# ISP6P5_SYS1 register map
Vendor: Texas Instruments
Peripheral module from a debugger description file (folder TDA2Px).
Registers are 32-bit, access per field, reset 0x0 unless marked. A register's access mark holds for its fields unless they carry their own. Offsets are as the file gives them; lines under a group give offsets from that group; [hi:lo] are bit positions; {n}, {i} and the like mark numbered series; 'fields as' and 'values as' point back to an identical list; <NAME> marks a mode.

## ISP6P5_SYS1
0x00 ISP5_REVISION ro reset not defined — IP Revision Identifier (X.Y.R) Used by software to track features, bugs, and compatibility
  [31:0] REVISION — IP Revision
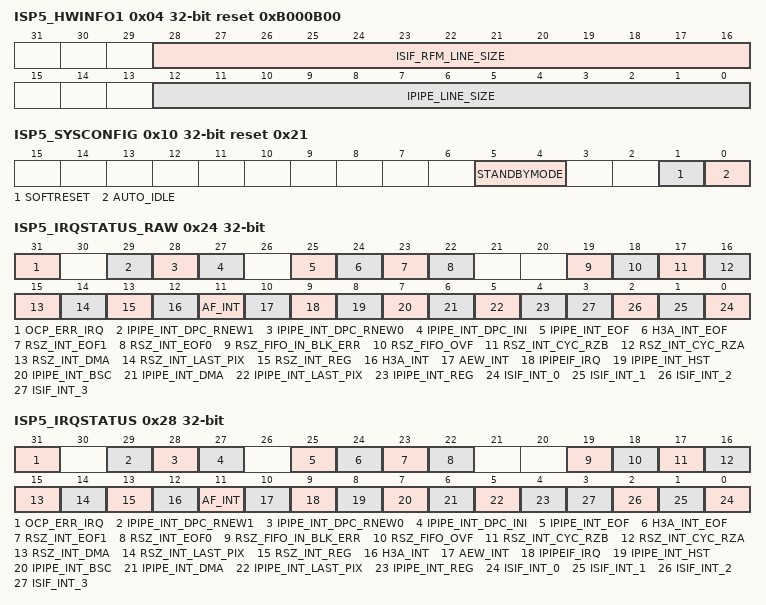
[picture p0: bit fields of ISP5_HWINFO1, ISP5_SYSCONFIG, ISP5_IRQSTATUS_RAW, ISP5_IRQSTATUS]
0x04 ISP5_HWINFO1 ro reset 0xB000B00 — GENERIC PARAMETER REGISTER Information about the IP module's hardware configuration. Actual field format and encoding is up to the module's designer to decide.
  [28:16] ISIF_RFM_LINE_SIZE — Memory line size for the data reformatter in the ISIF module.
  [12:0] IPIPE_LINE_SIZE — Memory line size for the IPIPE module
0x08 ISP5_HWINFO2 ro reset 0xB00 — GENERIC PARAMETER REGISTER Information about the IP module's hardware configuration. Actual field format and encoding is up to the module's designer to decide.
  [12:0] H3A_LINE_SIZE — Memory line size for the H3A module
0x10 ISP5_SYSCONFIG reset 0x21 — Clock management configuration
  [5:4] STANDBYMODE rw — Configuration of the local initiator state management mode. By definition, initiator may generate read/write transaction as long as it is out of STANDBY state.
    0=FORCE (Force-standby mode: local initiator is unconditionally placed in standby state. Backup mode, for debug only.); 1=NO (No-standby mode: local initiator is unconditionally placed out of standby state. Backup mode, for debug only.); 2=SMART (Smart-standby mode: local initiator standby status depends on local conditions, i.e. the module's functional requirement from the initiator. IP module shall not generate (initiator-related) wakeup events. Generation of the MStandby signal shall be initiated by the firmware by writing.MSTANDBY = ?1?.)
  [1] SOFTRESET rw — Software reset. The soft reset will cause the MStandby to be asserted as the reset value of theISP5_CTRL.MSTANDBY bit is 1. After a soft reset, the software shall ensure not to perform any access for 16 clock cycles (OCP-slave port frequency) after writing this bit. The OCP slave port is running at half the frequency of the functional clock. Before issuing a soft reset, the software shall ensure that no more traffic is being generated by the ISP5. Basically, it means that either the camera module shall be stopped from sending data and/or that the ISP5 modules are disabled. The last interrupt triggered by the ISP5 design upon completion of the frame processing is rsz_int_dma. This rsz_int_dma event shall be used to enable clean termination of the processing. The software shall wait a few hundred cycles to trigger the soft reset after upon assertion of the rsz_int_dma, this is to ensure that the BL is completely drained. Furthermore the software shall set the ISP5 in standbymode before issuing the soft reset: Set ISP5_SYSCONFIG.STANDBYMODE = 2 (smart standby) Set ISP5_CTRL.MSTANDBY to ?1? Poll for ISP5_CTRL.MSTANDBY_WAIT = 1. Then, the soft reset can be applied ISP5_SYSCONFIG.SOFTRESET = 1.
    0=DONE (Reset done, no pending action); 1=PENDING (Reset (software or other) ongoing)
  [0] AUTO_IDLE ro — Auto clock gating. Always enabled.
0x20 ISP5_IRQ_EOI — End Of Interrupt number specification
  [1:0] LINE_NUMBER rw — Software End Of Interrupt (EOI) control. Write number of interrupt output.
    0=READ0 (Reads always 0 (no EOI memory)); 1=EOI1 (EOI for interrupt output line #1); 3=EOI3 (EOI for interrupt output line #3); 2=EOI2 (EOI for interrupt output line #2)
0x24 ISP5_IRQSTATUS_RAW — Per-event raw interrupt status vector. Raw status is set even if event is not enabled. Write 1 to set the (raw) status, mostly for debug. The ISP5 outputs 4 interrupt lines ISP5_IRQ0 to ISP5_IRQ3. Any internal ISP5 event can be merged on the 4 lines. A same event shall be enabled on only one interrupt line. There is another interrupt register in the memory map, look for2
  [all] fields
    0=NOACTION; 1=SET (Set event (debug))
  [31] OCP_ERR_IRQ rw — An OCP error has been received on the ISP5 master port.
  [29] IPIPE_INT_DPC_RNEW1 rw
  [28] IPIPE_INT_DPC_RNEW0 rw
  [27] IPIPE_INT_DPC_INI rw
  [25] IPIPE_INT_EOF rw
  [24] H3A_INT_EOF rw
  [23] RSZ_INT_EOF1 rw — RESIZER module event: This event signals that the BL has received the eof signal from the resizer B engine which happens one the last transfer in the frame has happened. Note that because the BL has FIFOs it may take some additional time before true data transfter completion to memory.
  [22] RSZ_INT_EOF0 rw — RESIZER module event: This event signals that the BL has received the eof signal from the resizer A engine which happens one the last transfer in the frame has happened. Note that because the BL has FIFOs it may take some additional time before true data transfter completion to memory.
  [19] RSZ_FIFO_IN_BLK_ERR rw — This event signals that the minimum vertical blanking period has not been respected causing errors in the input data buffering submodule. This event will be triggered when the rsz_int_reg event of frame N is triggered before the rsz_int_dma of frame N + 1. This event would typically happen at the transition between two frames because there is not enough vertical blanking between frames: the firmware shall take care to ensure enough vertical blanking. The hardware cannot recover from this error. It will be required to perform a reset of the IP.
  [18] RSZ_FIFO_OVF rw — Resizer module overflow This event is set when overflow happens in the RESIZER module. This event would typically happen while processing a frame because the video port pixel clock is too high: the firmware shall take care to use a lower pixel clock at the input of the resizer module. Depending on the mode bein used, the overflow can happen at different places: 1. Bypass mode: overflow happened in the input circular buffer. 2. Pass through mode: overflow happened on the module output interface (MTC) 3. Normal resize mode: overflow happened in the input circular buffer. This event signals that overflow happened in the input data buffering submodule. 1. In normal resizer mode or bypass mode, this event will be triggered when the This event would typically happen while processing a frame because the video port pixel clock is too high: the firmware shall take care to use a lower pixel clock at the input of the resizer module. The hardware cannot recover from this error. It will be required to perform a reset of the IP.
  [17] RSZ_INT_CYC_RZB rw — RESIZER module event: This event is the circular interrupt for RESIZER #B. An event can be triggered every time thatRSZ_IRQ_RZB output lines have been written out to the RZB_SDR_Y buffer. The range can go from 1 to 8192 lines. Usually, this value should be such that the circular buffer vertical size (set by the RZB_SDR_Y_PTR_E register) is a multiple of RSZ_IRQ_RZB. Note that at the time the interrupt is triggered, the actual data write has not taken place. It may take a few hundred of cycles to complete the data write into system memory. This is not an issue since the start of the buffer is read first.
  [16] RSZ_INT_CYC_RZA rw — RESIZER module event: This event is the circular interrupt for RESIZER #A. An event can be triggered every time thatRSZ_IRQ_RZA output lines have been written out to the RZA_SDR_Y buffer. The range can go from 1 to 8192 lines. Usually, the circular buffer vertical size (set by the RZA_SDR_Y_PTR_E register) should be a multiple of RSZ_IRQ_RZA. Note that at the time the interrupt is triggered, the actual data write has not taken place. It may take a few hundred of cycles to complete the data write into system memory. This is not an issue since the start of the buffer is read first.
  [15] RSZ_INT_DMA rw — This event is triggered when the last eof (of the two MTC interfaces) is sent out to the BL and that the resizer core has returned to idle. rsz_int_dma is a true indication that all processing is finished for the particular frame on both resizer engines.
  [14] RSZ_INT_LAST_PIX rw — This event is triggered when the last pixel of the valid area is received.
  [13] RSZ_INT_REG rw — This event is triggered when the first pixel of the valid area is received. Shadowed registers can be updated at any time but the new value will take effect on the next rsz_int_reg event.
  [12] H3A_INT rw
  [11] AF_INT rw
  [10] AEW_INT rw
  [9] IPIPEIF_IRQ rw — IPIPEIF module interrupt
  [8] IPIPE_INT_HST rw
  [7] IPIPE_INT_BSC rw
  [6] IPIPE_INT_DMA rw
  [5] IPIPE_INT_LAST_PIX rw
  [4] IPIPE_INT_REG rw
  [n] ISIF_INT_{n} rw (n=0..3)
0x28 ISP5_IRQSTATUS — Per-event 'enabled' interrupt status vector. Enabled status isn't set unless event is enabled. Write 1 to clear the status after interrupt has been serviced (raw status gets cleared, i.e. even if not enabled). The ISP5 outputs 4 interrupt lines ISP5_IRQ0 to ISP5_IRQ3. Any internal ISP5 event can be merged on the 4 lines. A same event shall be enabled on only one interrupt line. There is another interrupt register in the memory map, look for2
  [all] fields
    0=NOACTION; 1=CLEAR (Clear (raw) event)
  [31] OCP_ERR_IRQ rw — An OCP error has been received on the ISP5 master port.
  [29] IPIPE_INT_DPC_RNEW1 rw
  [28] IPIPE_INT_DPC_RNEW0 rw
  [27] IPIPE_INT_DPC_INI rw
  [25] IPIPE_INT_EOF rw
  [24] H3A_INT_EOF rw
  [23] RSZ_INT_EOF1 rw — RESIZER module event: This event signals that the BL has received the eof signal from the resizer B engine which happens one the last transfer in the frame has happened. Note that because the BL has FIFOs it may take some additional time before true data transfter completion to memory.
  [22] RSZ_INT_EOF0 rw — RESIZER module event: This event signals that the BL has received the eof signal from the resizer A engine which happens one the last transfer in the frame has happened. Note that because the BL has FIFOs it may take some additional time before true data transfter completion to memory.
  [19] RSZ_FIFO_IN_BLK_ERR rw — This event signals that the minimum vertical blanking period has not been respected causing errors in the input data buffering submodule. This event will be triggered when the rsz_int_reg event of frame N is triggered before the rsz_int_dma of frame N + 1. This event would typically happen at the transition between two frames because there is not enough vertical blanking between frames: the firmware shall take care to ensure enough vertical blanking. The hardware cannot recover from this error. It will be required to perform a reset of the IP.
  [18] RSZ_FIFO_OVF rw — This event would typically happen while processing a frame because the video port pixel clock is too high: the firmware shall take care to use a lower pixel clock at the input of the resizer module. The hardware cannot recover from this error. It will be required to perform a reset of the IP.
  [17] RSZ_INT_CYC_RZB rw — RESIZER module event: This event is the circular interrupt for RESIZER #B. An event can be triggered every time thatRSZ_IRQ_RZB output lines have been written out to the RZB_SDR_Y buffer. The range can go from 1 to 8192 lines. Usually, this value should be such that the circular buffer vertical size (set by the RZB_SDR_Y_PTR_E register) is a multiple of RSZ_IRQ_RZB. Note that at the time the interrupt is triggered, the actual data write has not taken place. It may take a few hundred of cycles to complete the data write into system memory. This is not an issue since the start of the buffer is read first.
  [16] RSZ_INT_CYC_RZA rw — RESIZER module event: This event is the circular interrupt for RESIZER #A. An event can be triggered every time thatRSZ_IRQ_RZA output lines have been written out to the RZA_SDR_Y buffer. The range can go from 1 to 8192 lines. Usually, the circular buffer vertical size (set by the RZA_SDR_Y_PTR_E register) should be a multiple of RSZ_IRQ_RZA. Note that at the time the interrupt is triggered, the actual data write has not taken place. It may take a few hundred of cycles to complete the data write into system memory. This is not an issue since the start of the buffer is read first.
  [15] RSZ_INT_DMA rw — This event is triggered when the last eof (of the two MTC interfaces) is sent out to the BL and that the resizer core has returned to idle. rsz_int_dma is a true indication that all processing is finished for the particular frame on both resizer engines.
  [14] RSZ_INT_LAST_PIX rw — This event is triggered when the last pixel of the valid area is received.
  [13] RSZ_INT_REG rw — This event is triggered when the first pixel of the valid area is received. Shadowed registers can be updated at any time but the new value will take effect on the next rsz_int_reg event.
  [12] H3A_INT rw
  [11] AF_INT rw
  [10] AEW_INT rw
  [9] IPIPEIF_IRQ rw — IPIPEIF module interrupt
  [8] IPIPE_INT_HST rw
  [7] IPIPE_INT_BSC rw
  [6] IPIPE_INT_DMA rw
  [5] IPIPE_INT_LAST_PIX rw
  [4] IPIPE_INT_REG rw
  [n] ISIF_INT_{n} rw (n=0..3)
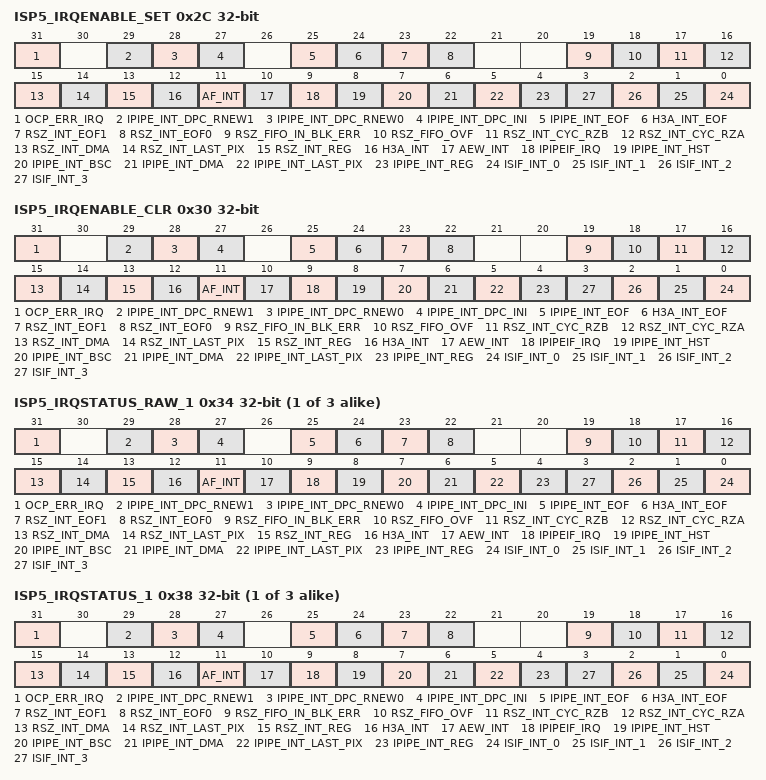
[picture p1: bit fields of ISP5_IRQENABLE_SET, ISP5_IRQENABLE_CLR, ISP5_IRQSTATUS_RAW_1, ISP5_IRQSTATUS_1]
0x2C ISP5_IRQENABLE_SET — Per-event interrupt enable bit vector. Write 1 to set (enable interrupt). Readout equal to corresponding _CLR register. The ISP5 outputs 4 interrupt lines ISP5_IRQ0 to ISP5_IRQ3. Any internal ISP5 event can be merged on the 4 lines. A same event shall be enabled on only one interrupt line. There is another interrupt register in the memory map, look for2.
  [all] fields
    0=NOACTION; 1=ENABLE (Enable interrupt)
  [31] OCP_ERR_IRQ rw — An OCP error has been received on the ISP5 master port.
  [29] IPIPE_INT_DPC_RNEW1 rw
  [28] IPIPE_INT_DPC_RNEW0 rw
  [27] IPIPE_INT_DPC_INI rw
  [25] IPIPE_INT_EOF rw
  [24] H3A_INT_EOF rw
  [23] RSZ_INT_EOF1 rw — RESIZER module event: This event signals that the BL has received the eof signal from the resizer B engine which happens one the last transfer in the frame has happened. Note that because the BL has FIFOs it may take some additional time before true data transfter completion to memory.
  [22] RSZ_INT_EOF0 rw — RESIZER module event: This event signals that the BL has received the eof signal from the resizer A engine which happens one the last transfer in the frame has happened. Note that because the BL has FIFOs it may take some additional time before true data transfter completion to memory.
  [19] RSZ_FIFO_IN_BLK_ERR rw — This event signals that the minimum vertical blanking period has not been respected causing errors in the input data buffering submodule. This event will be triggered when the rsz_int_reg event of frame N is triggered before the rsz_int_dma of frame N + 1. This event would typically happen at the transition between two frames because there is not enough vertical blanking between frames: the firmware shall take care to ensure enough vertical blanking. The hardware cannot recover from this error. It will be required to perform a reset of the IP.
  [18] RSZ_FIFO_OVF rw — This event would typically happen while processing a frame because the video port pixel clock is too high: the firmware shall take care to use a lower pixel clock at the input of the resizer module. The hardware cannot recover from this error. It will be required to perform a reset of the IP.
  [17] RSZ_INT_CYC_RZB rw — RESIZER module event: This event is the circular interrupt for RESIZER #B. An event can be triggered every time thatRSZ_IRQ_RZB output lines have been written out to the RZB_SDR_Y buffer. The range can go from 1 to 8192 lines. Usually, this value should be such that the circular buffer vertical size (set by the RZB_SDR_Y_PTR_E register) is a multiple of RSZ_IRQ_RZB. Note that at the time the interrupt is triggered, the actual data write has not taken place. It may take a few hundred of cycles to complete the data write into system memory. This is not an issue since the start of the buffer is read first.
  [16] RSZ_INT_CYC_RZA rw — RESIZER module event: This event is the circular interrupt for RESIZER #A. An event can be triggered every time thatRSZ_IRQ_RZA output lines have been written out to the RZA_SDR_Y buffer. The range can go from 1 to 8192 lines. Usually, the circular buffer vertical size (set by the RZA_SDR_Y_PTR_E register) should be a multiple of RSZ_IRQ_RZA. Note that at the time the interrupt is triggered, the actual data write has not taken place. It may take a few hundred of cycles to complete the data write into system memory. This is not an issue since the start of the buffer is read first.
  [15] RSZ_INT_DMA rw — This event is triggered when the last eof (of the two MTC interfaces) is sent out to the BL and that the resizer core has returned to idle. rsz_int_dma is a true indication that all processing is finished for the particular frame on both resizer engines.
  [14] RSZ_INT_LAST_PIX rw — This event is triggered when the last pixel of the valid area is received.
  [13] RSZ_INT_REG rw — This event is triggered when the first pixel of the valid area is received. Shadowed registers can be updated at any time but the new value will take effect on the next rsz_int_reg event.
  [12] H3A_INT rw
  [11] AF_INT rw
  [10] AEW_INT rw
  [9] IPIPEIF_IRQ rw — IPIPEIF module interrupt
  [8] IPIPE_INT_HST rw
  [7] IPIPE_INT_BSC rw
  [6] IPIPE_INT_DMA rw
  [5] IPIPE_INT_LAST_PIX rw
  [4] IPIPE_INT_REG rw
  [n] ISIF_INT_{n} rw (n=0..3)
0x30 ISP5_IRQENABLE_CLR — Per-event interrupt enable bit vector. Write 1 to clear (disable interrupt). Readout equal to corresponding _SET register. The ISP5 outputs 4 interrupt lines ISP5_IRQ0 to ISP5_IRQ3. Any internal ISP5 event can be merged on the 4 lines. A same event shall be enabled on only one interrupt line. There is another interrupt register in the memory map, look for2.
  [all] fields
    0=NOACTION; 1=DISABLE (Disable interrupt)
  [31] OCP_ERR_IRQ rw — An OCP error has been received on the ISP5 master port.
  [29] IPIPE_INT_DPC_RNEW1 rw
  [28] IPIPE_INT_DPC_RNEW0 rw
  [27] IPIPE_INT_DPC_INI rw
  [25] IPIPE_INT_EOF rw
  [24] H3A_INT_EOF rw
  [23] RSZ_INT_EOF1 rw — RESIZER module event: This event signals that the BL has received the eof signal from the resizer B engine which happens one the last transfer in the frame has happened. Note that because the BL has FIFOs it may take some additional time before true data transfter completion to memory.
  [22] RSZ_INT_EOF0 rw — RESIZER module event: This event signals that the BL has received the eof signal from the resizer A engine which happens one the last transfer in the frame has happened. Note that because the BL has FIFOs it may take some additional time before true data transfter completion to memory.
  [19] RSZ_FIFO_IN_BLK_ERR rw — This event signals that the minimum vertical blanking period has not been respected causing errors in the input data buffering submodule. This event will be triggered when the rsz_int_reg event of frame N is triggered before the rsz_int_dma of frame N + 1. This event would typically happen at the transition between two frames because there is not enough vertical blanking between frames: the firmware shall take care to ensure enough vertical blanking. The hardware cannot recover from this error. It will be required to perform a reset of the IP.
  [18] RSZ_FIFO_OVF rw — This event would typically happen while processing a frame because the video port pixel clock is too high: the firmware shall take care to use a lower pixel clock at the input of the resizer module. The hardware cannot recover from this error. It will be required to perform a reset of the IP.
  [17] RSZ_INT_CYC_RZB rw — RESIZER module event: This event is the circular interrupt for RESIZER #B. An event can be triggered every time thatRSZ_IRQ_RZB output lines have been written out to the RZB_SDR_Y buffer. The range can go from 1 to 8192 lines. Usually, this value should be such that the circular buffer vertical size (set by the RZB_SDR_Y_PTR_E register) is a multiple of RSZ_IRQ_RZB. Note that at the time the interrupt is triggered, the actual data write has not taken place. It may take a few hundred of cycles to complete the data write into system memory. This is not an issue since the start of the buffer is read first.
  [16] RSZ_INT_CYC_RZA rw — RESIZER module event: This event is the circular interrupt for RESIZER #A. An event can be triggered every time thatRSZ_IRQ_RZA output lines have been written out to the RZA_SDR_Y buffer. The range can go from 1 to 8192 lines. Usually, the circular buffer vertical size (set by the RZA_SDR_Y_PTR_E register) should be a multiple of RSZ_IRQ_RZA. Note that at the time the interrupt is triggered, the actual data write has not taken place. It may take a few hundred of cycles to complete the data write into system memory. This is not an issue since the start of the buffer is read first.
  [15] RSZ_INT_DMA rw — RESIZER module event: This event is triggered when the last eof (of the two MTC interfaces) is sent out to the BL and that the resizer core has returned to idle. rsz_int_dma is a true indication that all processing is finished for the particular frame on both resizer engines.
  [14] RSZ_INT_LAST_PIX rw — RESIZER module event: This event is triggered when the last pixel of the valid area is received.
  [13] RSZ_INT_REG rw — RESIZER module event: This event is triggered when the first pixel of the valid area is received. Shadowed registers can be updated at any time but the new value will take effect on the next rsz_int_reg event.
  [12] H3A_INT rw
  [11] AF_INT rw
  [10] AEW_INT rw
  [9] IPIPEIF_IRQ rw — IPIPEIF module interrupt
  [8] IPIPE_INT_HST rw
  [7] IPIPE_INT_BSC rw
  [6] IPIPE_INT_DMA rw
  [5] IPIPE_INT_LAST_PIX rw
  [4] IPIPE_INT_REG rw
  [n] ISIF_INT_{n} rw (n=0..3)
{0x24+0x10*i} ISP5_IRQSTATUS_RAW_{i} (i=1..3) — Per-event raw interrupt status vector. Raw status is set even if event is not enabled. Write 1 to set the (raw) status, mostly for debug. The ISP5 outputs 4 interrupt lines ISP5_IRQ0 to ISP5_IRQ3. Any internal ISP5 event can be merged on the 4 lines. A same event shall be enabled on only one interrupt line. There is another interrupt register in the memory map, look for2
  fields as ISP5_IRQSTATUS_RAW
{0x28+0x10*i} ISP5_IRQSTATUS_{i} (i=1..3) — Per-event 'enabled' interrupt status vector. Enabled status isn't set unless event is enabled. Write 1 to clear the status after interrupt has been serviced (raw status gets cleared, i.e. even if not enabled). The ISP5 outputs 4 interrupt lines ISP5_IRQ0 to ISP5_IRQ3. Any internal ISP5 event can be merged on the 4 lines. A same event shall be enabled on only one interrupt line. There is another interrupt register in the memory map, look for2
  fields as ISP5_IRQSTATUS
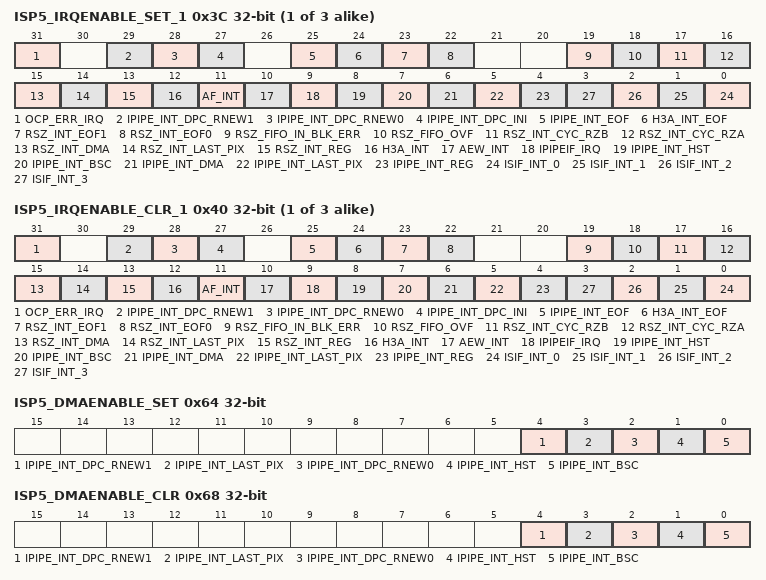
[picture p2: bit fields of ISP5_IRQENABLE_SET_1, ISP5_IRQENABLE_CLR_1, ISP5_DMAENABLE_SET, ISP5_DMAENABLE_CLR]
{0x2C+0x10*i} ISP5_IRQENABLE_SET_{i} (i=1..3) — Per-event interrupt enable bit vector. Write 1 to set (enable interrupt). Readout equal to corresponding _CLR register. The ISP5 outputs 4 interrupt lines ISP5_IRQ0 to ISP5_IRQ3. Any internal ISP5 event can be merged on the 4 lines. A same event shall be enabled on only one interrupt line. There is another interrupt register in the memory map, look for2.
  fields as ISP5_IRQENABLE_SET
{0x30+0x10*i} ISP5_IRQENABLE_CLR_{i} (i=1..3) — Per-event interrupt enable bit vector. Write 1 to clear (disable interrupt). Readout equal to corresponding _SET register. The ISP5 outputs 4 interrupt lines ISP5_IRQ0 to ISP5_IRQ3. Any internal ISP5 event can be merged on the 4 lines. A same event shall be enabled on only one interrupt line. There is another interrupt register in the memory map, look for2.
  fields as ISP5_IRQENABLE_CLR
0x64 ISP5_DMAENABLE_SET — Per-line DMA enable bit vector Write 1 to set (enable DMA request generation). Readout equal to corresponding _CLR register.
  [all] fields
    0=NOACTION; 1=ENABLE (Enable DMA)
  [4] IPIPE_INT_DPC_RNEW1 rw — Enable for ISP5 DMA request generation on line #2 This DMA request shall be set to transfer the DPC data from memory to the IPIPE internal RAM.
  [3] IPIPE_INT_LAST_PIX rw — Enable for ISP5 DMA request generation on line #3 This DMA request shall be set to transfer the GAMMA data from memory to the IPIPE internal RAM or to initialize the DPC table. One shall set theISP5_CTRL.DMA3_CFG register before enabling this DMA request.
  [2] IPIPE_INT_DPC_RNEW0 rw — Enable for ISP5 DMA request generation on line #2 This DMA request shall be set to transfer the DPC data from memory to the IPIPE internal RAM.
  [1] IPIPE_INT_HST rw — Enable for ISP5 DMA request generation on line #1 This DMA request shall be set to transfer the HIST data from the IPIPE internal RAM to memory.
  [0] IPIPE_INT_BSC rw — Enable for ISP5 DMA request generation on line #0 This DMA request shall be set to transfer the BSC data from the IPIPE internal RAM to memory.
0x68 ISP5_DMAENABLE_CLR — Per-line DMA clear bit vector Write 1 to clear (disable DMA request generation). Readout equal to corresponding _SET register.
  [all] fields
    0=NOACTION; 1=DISABLE (Disable DMA)
  [4] IPIPE_INT_DPC_RNEW1 rw — Clear for ISP5 DMA request generation on line ISP5_DMA_REQ[2]. This DMA request shall be set to transfer the DPC data from memory to the IPIPE internal RAM.
  [3] IPIPE_INT_LAST_PIX rw — Clear for ISP5 DMA request generation on ISP5_DMA_REQ[3]. This DMA request shall be set to transfer the GAMMA data from memory to the IPIPE internal RAM.
  [2] IPIPE_INT_DPC_RNEW0 rw — Clear for ISP5 DMA request generation on ISP5_DMA_REQ[2]. This DMA request shall be set to transfer the DPC data from memory to the IPIPE internal RAM.
  [1] IPIPE_INT_HST rw — Clear for ISP5 DMA request generation on ISP5_DMA_REQ[1]. This DMA request shall be set to transfer the HIST data from the IPIPE internal RAM to memory.
  [0] IPIPE_INT_BSC rw — Clear for ISP5 DMA request generation on ISP5_DMA_REQ[0]. This DMA request shall be set to transfer the BSC data from the IPIPE internal RAM to memory.
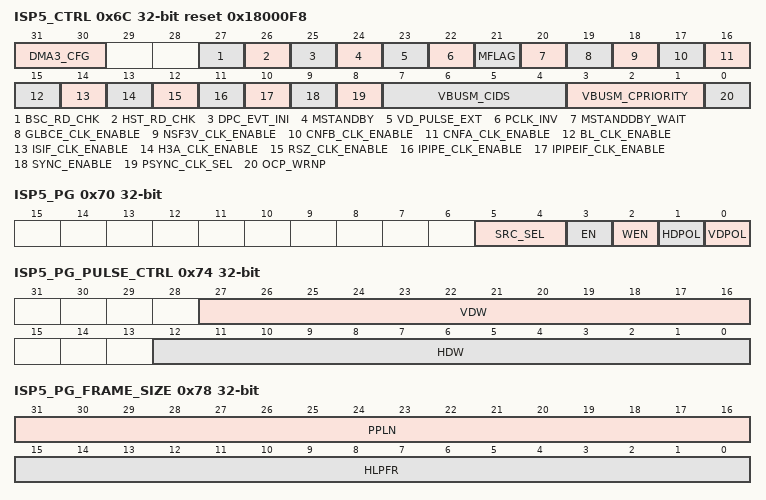
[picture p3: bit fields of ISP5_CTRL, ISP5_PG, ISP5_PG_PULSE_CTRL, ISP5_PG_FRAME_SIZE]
0x6C ISP5_CTRL reset 0x18000F8 — ISP5 CONTROL REGISTER
  [31:30] DMA3_CFG rw — This bitfield selects the DMA transfer configuration which is used with the ISP5_DMA_REQ[3] DMA request signal. This DMA request is generated from IPIPE_INT_LAST_PIXEL event. One can choose to use this DMA request to either transfer the DPC initialization data, the gamma table or both.
    0=NEWENUM1 (No DMA request associated with ISP5_DMA_REQ[3].); 1=NEWENUM2 (DPC DMA request associated with ISP5_DMA_REQ[3]. Expected DMA transfer size is 2 KBytes in the range 0x8000-0x87FF. DPC_EVT_INI shall be set to 0.); 3=NEWENUM4 (DPC + GAMMA DMA request associated with ISP5_DMA_REQ[3]. Expected DMA transfer size is 8 KBytes in the range 0x8000-0x87FF and 0xA800-0xBFFF. DPC_EVT_INI shall be set to 0.); 2=NEWENUM3 (GAMMA DMA request associated with ISP5_DMA_REQ[3]. Expected DMA transfer size is 6 KBytes in the range 0xA800-0xBFFF.)
  [27] BSC_RD_CHK rw — When the BSC computation is enabled and the BSC DMA request not used to read out the data, this register enables to ensure that the data were read fast enough, else an interrupt IPIPE_BSC_ERR is triggered. The hardware sets automatically this bit to 1 when software can start reading the memory. It is the software responsibility to set this bit to 0 after reading the data. Once the CPU has read the BSC data, it SHALL clear this register, else the PIPE_BSC_ERR will occur.
    0=NEWENUM1 (No interrupt generation can happen); 1=NEWENUM2 (The CPU can read the data from the memory. Needs to complete fast enough to avoid the interrupt generation.)
  [26] HST_RD_CHK rw — When the HISTOGRAM computation is enabled and the HST DMA request not used to read out the data, this register enables to ensure that the data were read fast enough, else an interrupt IPIPE_HST_ERR is triggered. The hardware sets automatically this bit to 1 when software can start reading the memory. It is the software responsibility to set this bit to 0 after reading the data. Once the CPU has read the histogram data, it SHALL clear this register, else the PIPE_HST_ERR will occur.
    values as BSC_RD_CHK
  [25] DPC_EVT_INI rw — Select the IPIPE module event to be used to generate the DMA requests for the DPC submodule.
    0=NEWENUM1 (IPIPE_INT_LAST_PIX event is selected.); 1=NEWENUM2 (IPIPE_INT_DPC_INI event is selected.)
  [24] MSTANDBY rw — MStandby signal assertion and de-assertion control for power management transitions. After software reset, this bit is asserted. Write '1' to transition from normal mode to idle mode. The firmware needs to ensure that no more ISP5 processing is ongoing before setting up this bit. Write '0' to transition from idle mode to normal mode. The software should pollISP5_CTRL.MSTANDBY_WAIT = ?0? after writing ISP5_CTRL.MSTANDBY = ?0? in a transition from idle to normal mode.
    0=NEWENUM1 (De-assert MStandby signal. May not be immediate due to power management handshaking btw the MStandby and Wait signals.); 1=NEWENUM2 (Assert MStandby signal)
  [23] VD_PULSE_EXT rw — VD pulse extension enable This bit enables or disables the VD extension bridge. By default, the bridge is enabled. At ISS level, it is expected that IPS5_CTRL.VD_PULSE_EXT = 1 when the VPORT gets data from the CSI2 RX module and IPS5_CTRL.VD_PULSE_EXT = 0 when the VPORT gets data from the parallel interface or the CCP2 RX module. There shall be at least three clock cycles between the time this bit is modified and the HD/VD pulse for start of frame comes.
    0=NEWENUM1 (Disabled); 1=NEWENUM2 (Enabled)
  [22] PCLK_INV rw — Pixel clock inversion This bit enables or disables pixel clock inversion. The ISP5 always samples the data on the rising edge of the pixel clock. Enabling the inversion shifts the resampling period by 1/2 a pixel clock period. PCLK needs to be disabled at ISS level before setting this bit.
    0=NEWENUM1 (Normal); 1=NEWENUM2 (Inversed)
  [21] MFLAG rw — MFlag signal generation control This bit controls how the OCP MFlag signal is generated on the ISS NOC.
    0=NEWENUM1 (The MFlag value is dynamic.); 1=NEWENUM2 (The MFlag value is static. The value is set with the.VBUSM_CPRIORITY bitfield.)
  [20] MSTANDDBY_WAIT ro — MStandby / Wait power management status bit. The power management framework of the ISP5 is based on the handshaking of the MStandby and Wait signals. The software is not supposed to write insidle the ISP5 slave port and initiate traffic whenISP5_CTRL.MSTANDBY bit is written. The software can poll this bit to know when MStandby signal is deasserted.
    0=NEWENUM1 (MStandby signal is de-asserted); 1=NEWENUM2 (MStandby signal is asserted)
  [19] GLBCE_CLK_ENABLE rw — GLBCE clock enable
    0=NEWENUM1 (Disable); 1=NEWENUM2 (Enable)
  [18] NSF3V_CLK_ENABLE rw — NSF3V clock enable
    0=NEWENUM1 (Disable); 1=NEWENUM2 (Enable)
  [17] CNFB_CLK_ENABLE rw — CNFB clock enable
    0=NEWENUM1 (Disable. Since CNF-B is removed , it doesn't have any effect); 1=NEWENUM2 (Enable. Since CNF-B is removed , it doesn't have any effect.)
  [16] CNFA_CLK_ENABLE rw — CNFA clock enable
    0=NEWENUM1 (Disable); 1=NEWENUM2 (Enable)
  [15] BL_CLK_ENABLE rw — BL clock enable
    0=NEWENUM1 (Disable); 1=NEWENUM2 (Enable)
  [14] ISIF_CLK_ENABLE rw — ISIF clock enable The ISP5 will return OCP_ERROR if one tries to program the module MMR or memory when the clock is disabled. There shall be at least three clock cycles between the time this bit is modified and the HD/VD pulse for start of frame comes.
    0=NEWENUM1 (Disable); 1=NEWENUM2 (Enable)
  [13] H3A_CLK_ENABLE rw — H3A clock enable The ISP5 will return OCP_ERROR if one tries to program the module MMR or memory when the clock is disabled.
    0=NEWENUM1 (Disable); 1=NEWENUM2 (Enable)
  [12] RSZ_CLK_ENABLE rw — RESIZER clock enable The ISP5 will return OCP_ERROR if one tries to program the module MMR or memory when the clock is disabled.
    0=NEWENUM1 (Disable); 1=NEWENUM2 (Enable)
  [11] IPIPE_CLK_ENABLE rw — IPIPE clock enable The ISP5 will return OCP_ERROR if one tries to program the module MMR or memory when the clock is disabled. If DPC is working before NSF3V (working as pre-NSF3V DPC), this bit must be asserted for SW to access DPC MMR entries.
    0=NEWENUM1 (Disable); 1=NEWENUM2 (Enable)
  [10] IPIPEIF_CLK_ENABLE rw — IPIPEIF clock enable The ISP5 will return OCP_ERROR if one tries to program the module MMR or memory when the clock is disabled.
    0=NEWENUM1 (Disable); 1=NEWENUM2 (Enable)
  [9] SYNC_ENABLE rw — PCLK Sync module enable
    0=NEWENUM1 (Disable. Shall only be used when the video port is not receiving data, e.g., data is read from the IPIPEIF module memory read port.); 1=NEWENUM2 (Enable. Shall be used when the video port is receiving data.)
  [8] PSYNC_CLK_SEL rw — PCLK Sync clock select. This bit selects the clock which is used to resynchronize the input pixel clock.
    0=NEWENUM1 (Use ISP6_CFG_CLK. Can be used if the input pixel clock is always lower than 213 MHz. Also, this option must not be chosen if DPC is used with CAL if (CAL - DPC - NSF3V - CAL case.)); 1=NEWENUM2 (ISP6_FUNC_CLK. Shall be used if the pixel clock is higher than 213 MHz or DPC is used with CAL port. (CAL - DPC - NSF3V - CAL))
  [7:4] VBUSM_CIDS rw — BL MAX VBUSM CIDs The BL module supports up to 16 CIDs/tags. This bitfield setsup the maximum number of CISs/tags that the BL can use. The actual number of CIDs/tags is setup by VBUSM_CIDS + 1. Tag number 0 to VBUSM_CIDS are used.
  [3:1] VBUSM_CPRIORITY rw — BL VBUSM priority setting
    {v}=NEWENUM{v+1} (Normal Priority VBUSM cpriority[2:0] = {v}) (v=4..7); 1=NEWENUM2 (High Priority VBUSM cpriority[2:0] = 1); 0=NEWENUM1 (High Priority VBUSM cpriority[2:0] = 0); 2=NEWENUM3 (Medium Priority VBUSM cpriority[2:0] = 2); 3=NEWENUM4 (Medium Priority VBUSM cpriority[2:0] = 3)
  [0] OCP_WRNP rw — ISP5 OCP master port non-posted write control.
    0=NEWENUM1 (All writes are non posted.); 1=NEWENUM2 (All writes are posted.)
0x70 ISP5_PG — PATTERN GENERATOR REGISTER
  [5:4] SRC_SEL rw — Input mux selection
    0=NEWENUM1 (ISP5 video port is selected.); 1=NEWENUM2 (Reserved); 3=NEWENUM4 (Pattern generator is selected.); 2=NEWENUM3 (Reserved)
  [3] EN rw
    0=NEWENUM1 (Pattern generator off); 1=NEWENUM2 (Enable pattern generator)
  [2] WEN rw
    0=NEWENUM1 (WEN is always activated); 1=NEWENUM2 (WEN is on 8 cycles and off 8 cycles)
  [1] HDPOL rw
    0=NEWENUM1 (Active high); 1=NEWENUM2 (Active low)
  [0] VDPOL rw
    0=NEWENUM1 (Active high); 1=NEWENUM2 (Active low)
0x74 ISP5_PG_PULSE_CTRL — PATTERN GENERATOR REGISTER
  [27:16] VDW rw — Pattern generator VD width Width = VDW+1
  [12:0] HDW rw — Pattern generator HD width Width = HDW+1
0x78 ISP5_PG_FRAME_SIZE rw — PATTERN GENERATOR REGISTER
  [31:16] PPLN — Pattern Generator: pixels per line, PPLN+1
  [15:0] HLPFR — Pattern Generator: half lines per frame, HLPFR+1
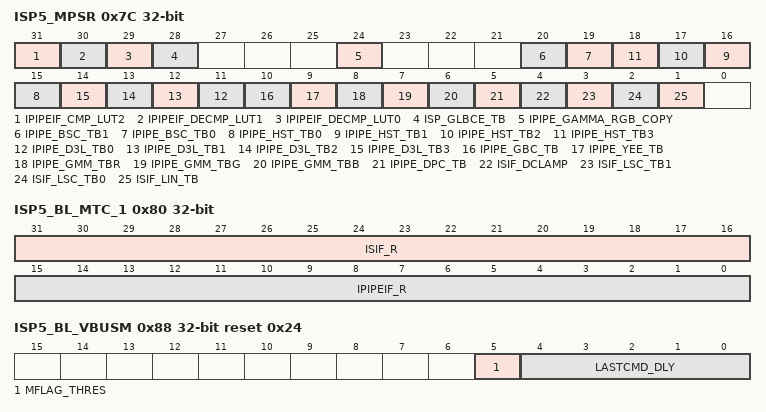
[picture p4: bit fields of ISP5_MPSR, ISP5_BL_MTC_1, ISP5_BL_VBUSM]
0x7C ISP5_MPSR — ISP5 memory access register. One need to pay attention when setting the bit fields in this register such that there is no conflict between the cpu and module accesses. Usually, the ISP5 modules shall have access to the memories and it's only when the isp5 is idle (vertical blanking period or module disabled that the cpu can access the memories. CPU has memory access If the cpu has memory access (read or write) and CPU has priority, it will cause data corruption if the module tries to perform concurrent memory accesses. The module cannot know that the read or write access has not taken place because of cpu accesses.
  [31] IPIPEIF_CMP_LUT2 rw — IPIPEIF Companding LUT memory access priority.
    0=NEWENUM1 (MODULE access has higher priority.); 1=NEWENUM2 (CPU access has higher priority.)
  [30] IPIPEIF_DECMP_LUT1 rw — IPIPEIF Memory Read path Decompanding LUT memory access priority.
    values as IPIPEIF_CMP_LUT2
  [29] IPIPEIF_DECMP_LUT0 rw — IPIPEIF VPORT Decompanding LUT memory access priority.
    0=NEWENUM1 (MODULE access has higher priority); 1=NEWENUM2 (CPU access has higher priority)
  [28] ISP_GLBCE_TB rw — ISP GLBCE TB memory access priority This memory is expected to be written during ISP5 initialization and potentially updated during vertical blanking periods.
    0=NEWENUM1 (MODULE access has higher priority); 1=NEWENUM2 (CPU access has higher priority.)
  [24] IPIPE_GAMMA_RGB_COPY rw — GAMMA table RGB Copy This bit shall be enable when one wants to use the same Gamma table for the R, G and B color components. When the CPU writes the R table, it is automatically copied to the G and B tables if this bit is set.
    0=NEWENUM1 (Copy disable Independent RGB gamma table); 1=NEWENUM2 (Copy enable Common RGB Gamma table)
  [20] IPIPE_BSC_TB1 rw — IPIPE BSC TB1 memory access priority This memory is expected to be read by the CPU or the DMA to get BSC information during vertical blanking period.
    values as ISP_GLBCE_TB
  [19] IPIPE_BSC_TB0 rw — IPIPE BSC TB0 memory access priority This memory is expected to be read by the CPU or the DMA to get BSC information during vertical blanking period.
    values as ISP_GLBCE_TB
  [n+15] IPIPE_HST_TB{n} rw (n=0..3) — IPIPE histogram memory #{n} access priority This memory is expected to be read by the CPU or the DMA to get HST information during vertical blanking period.
    values as ISP_GLBCE_TB
  [n+11] IPIPE_D3L_TB{n} rw (n=0..3) — D3L TB{n} memory access priority This memory is expected to be written during ISP5 initialization and potentially updated during vertical blanking periods.
    values as ISP_GLBCE_TB
  [10] IPIPE_GBC_TB rw — IPIPE GBC TB memory access priority This memory is expected to be written during ISP5 initialization and potentially updated during vertical blanking periods.
    values as ISP_GLBCE_TB
  [9] IPIPE_YEE_TB rw — YEE TB memory access priority This memory is expected to be written during ISP5 initialization and potentially updated during vertical blanking periods.
    values as ISP_GLBCE_TB
  [8] IPIPE_GMM_TBR rw — IPIPE Gamma LUT R memory arbitration This memory is expected to be written during ISP5 initialization and potentially updated during vertical blanking periods.
    values as ISP_GLBCE_TB
  [7] IPIPE_GMM_TBG rw — IPIPE Gamma LUT G memory arbitration This memory is expected to be written during ISP5 initialization and potentially updated during vertical blanking periods.
    values as ISP_GLBCE_TB
  [6] IPIPE_GMM_TBB rw — IPIPE Gamma LUT B memory arbitration This memory is expected to be written during ISP5 initialization and potentially updated during vertical blanking periods.
    values as ISP_GLBCE_TB
  [5] IPIPE_DPC_TB rw — IPIPE defect pixel memory arbitration This memory is expected to be written during ISP5 initialization and potentially updated during vertical blanking periods.
    values as ISP_GLBCE_TB
  [4] ISIF_DCLAMP rw — ISIF DC accumulation memory arbitration This memory is expected to be written during ISP5 initialization and potentially updated during vertical blanking periods.
    values as ISP_GLBCE_TB
  [3] ISIF_LSC_TB1 rw — ISIF LSC memory 1 access This memory is expected to be written during ISP5 initialization and potentially updated during vertical blanking periods.
    0=NEWENUM1 (MODULE has memory access When the module has memory access, the potential concurrent CPU accesses (on the ISP5 memory map) to read the memory are stalled. The CPU will eventually get back the data during the horizontal or vertical blanking periods when the module is not making access anymore.); 1=NEWENUM2 (CPU has memory access When the cpu has memory access (read or write), it will cause data corruption if the module tries to perform concurrent memory accesses. The module cannot know that the read or write access has not taken place because of cpu accesses.)
  [2] ISIF_LSC_TB0 rw — ISIF LSC memory 0 access This memory is expected to be written during ISP5 initialization and potentially updated during vertical blanking periods.
    0=NEWENUM1 (MODULE has memory access. When the module has memory access, the potential concurrent CPU accesses (on the ISP5 memory map) to read the memory are stalled. The CPU will eventually get back the data during the horizontal or vertical blanking periods when the module is not making access anymore.); 1=NEWENUM2 (CPU has memory access When the cpu has memory access (read or write), it will cause data corruption if the module tries to perform concurrent memory accesses. The module cannot know that the read or write access has not taken place because of cpu accesses.)
  [1] ISIF_LIN_TB rw — ISIF linearity compensation memory arbitration This memory is expected to be written during ISP5 initialization and potentially updated during vertical blanking periods.
    values as ISP_GLBCE_TB
0x80 ISP5_BL_MTC_1 rw — MEMORY REQUEST MINIMUM INTERVAL REGISTER
  [31:16] ISIF_R — Sets the minimum interval btw two consecutive memory requests for the ISIF-Read port. Specified in number of interface clock cycles.
  [15:0] IPIPEIF_R — Sets the minimum interval btw two consecutive memory requests for the IPIPEIF-Read port. Specified in number of interface clock cycles.
0x84 ISP5_BL_MTC_2 — MEMORY REQUEST MINIMUM INTERVAL REGISTER
  [31:16] H3A_W rw — Sets the minimum interval btw two consecutive memory requests for the H3A-Write port. Specified in number of interface clock cycles.
0x88 ISP5_BL_VBUSM reset 0x24 — BL VBUSM TUNING REGISTER The settings in the register are static and not expected to be modified dynamically.
  [5] MFLAG_THRES rw — MFLAG Threshold value The value of this bit field is a threshold which is compared to the MFlag output of the ISP5. If the BL MFlag signal is greater or equal to this thresold the last beat of the VBUSM command is delayed by LASTCMD_DLY cycles. Only values 0, 1 are valid, the least significant bit is tied off to 1 to make a 2-bit bitfield.
    0=NEWENUM1 (Thres = 1); 1=NEWENUM2 (Thres = 3)
  [4:0] LASTCMD_DLY rw — The value of this bitfield represents a delay expressed in cycles (L3 clock). This value is used to delay the last beat of the VBUSM command such that the ISP5 does not loose arbitration at the NOC level because the BL does not generate back to back requests by default. The last beat is delayed untill the counter expires or the new request is accepted. This delay is used when the MFlag output of the ISP5 is greater or equal to MFLAG_THRES. One can set this value to 0 to disable the last command beat delay.
